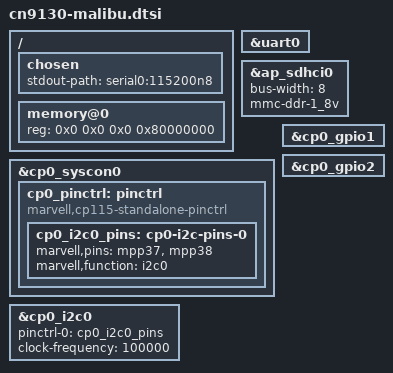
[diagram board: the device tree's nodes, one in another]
// SPDX-License-Identifier: GPL-2.0+
/*
 * Copyright (C) 2022 Gateworks Corporation
 */

#include "cn9130.dtsi" /* include SoC device tree */

#include <dt-bindings/gpio/gpio.h>

/ {
	chosen {
		stdout-path = "serial0:115200n8";
	};

	memory@0 {
		device_type = "memory";
		reg = <0x0 0x0 0x0 0x80000000>;
	};
};

&uart0 {
	status = "okay";
};

/* on-board eMMC */
&ap_sdhci0 {
	pinctrl-names = "default";
	bus-width = <8>;
	status = "okay";
	mmc-ddr-1_8v;
};

&cp0_syscon0 {
	cp0_pinctrl: pinctrl {
		compatible = "marvell,cp115-standalone-pinctrl";

		cp0_i2c0_pins: cp0-i2c-pins-0 {
			marvell,pins = "mpp37", "mpp38";
			marvell,function = "i2c0";
		};
	};
};

&cp0_gpio1 {
	status = "okay";
};

&cp0_gpio2 {
	status = "okay";
};

&cp0_i2c0 {
	pinctrl-names = "default";
	pinctrl-0 = <&cp0_i2c0_pins>;
	status = "okay";
	clock-frequency = <100000>;
};
